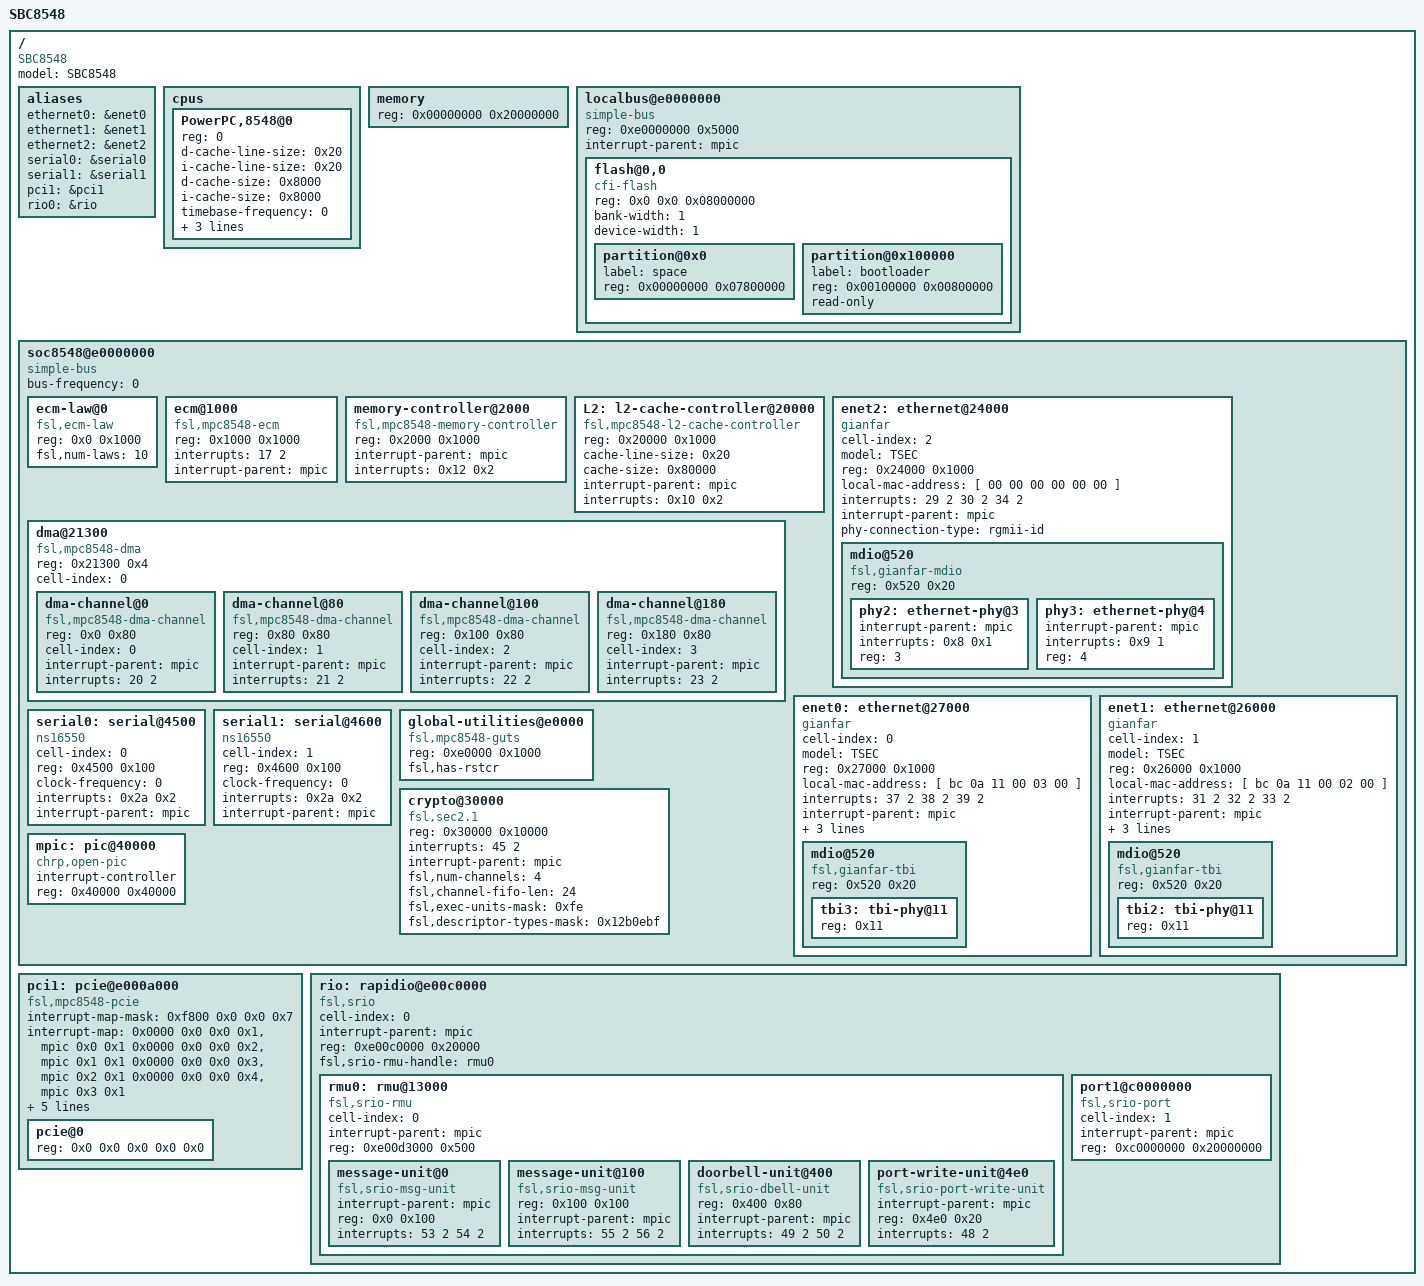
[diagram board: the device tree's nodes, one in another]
/*
 * SBC8548 Device Tree Source
 *
 * Copyright 2007 Wind River Systems Inc.
 *
 * Paul Gortmaker (see MAINTAINERS for contact information)
 *
 * This program is free software; you can redistribute  it and/or modify it
 * under  the terms of  the GNU General  Public License as published by the
 * Free Software Foundation;  either version 2 of the  License, or (at your
 * option) any later version.
 */


/dts-v1/;

/ {
	model = "SBC8548";
	compatible = "SBC8548";
	#address-cells = <1>;
	#size-cells = <1>;

	aliases {
		ethernet0 = &enet0;
                ethernet1 = &enet1;
                ethernet2 = &enet2;
		serial0 = &serial0;
		serial1 = &serial1;
		pci1 = &pci1;
		rio0 = &rio;
	};

	cpus {
		#address-cells = <1>;
		#size-cells = <0>;

		PowerPC,8548@0 {
			device_type = "cpu";
			reg = <0>;
			d-cache-line-size = <0x20>;	// 32 bytes
			i-cache-line-size = <0x20>;	// 32 bytes
			d-cache-size = <0x8000>;	// L1, 32K
			i-cache-size = <0x8000>;	// L1, 32K
			timebase-frequency = <0>;	// From uboot
			bus-frequency = <0>;
			clock-frequency = <0>;
			next-level-cache = <&L2>;
		};
	};

	memory {
		device_type = "memory";
		reg = <0x00000000 0x20000000>;
	};

	localbus@e0000000 {
		#address-cells = <2>;
		#size-cells = <1>;
		compatible = "simple-bus";
		reg = <0xe0000000 0x5000>;
		interrupt-parent = <&mpic>;

		ranges = <0x0 0x0 0xf8000000 0x08000000>;	/*64MB Flash*/


		flash@0,0 {
			#address-cells = <1>;
			#size-cells = <1>;
			compatible = "cfi-flash";
			reg = <0x0 0x0 0x08000000>;
			bank-width = <1>;
			device-width = <1>;
			partition@0x0 {
				label = "space";
				reg = <0x00000000 0x07800000>;
			};
			partition@0x100000 {
				label = "bootloader";
				reg = <0x00100000 0x00800000>;
				read-only;
			};
		};

		};

	soc8548@e0000000 {
		#address-cells = <1>;
		#size-cells = <1>;
		device_type = "soc";
		ranges = <0x00000000 0xe0000000 0x00100000>;
		bus-frequency = <0>;
		compatible = "simple-bus";

		ecm-law@0 {
			compatible = "fsl,ecm-law";
			reg = <0x0 0x1000>;
			fsl,num-laws = <10>;
		};

		ecm@1000 {
			compatible = "fsl,mpc8548-ecm", "fsl,ecm";
			reg = <0x1000 0x1000>;
			interrupts = <17 2>;
			interrupt-parent = <&mpic>;
		};

		memory-controller@2000 {
			compatible = "fsl,mpc8548-memory-controller";
			reg = <0x2000 0x1000>;
			interrupt-parent = <&mpic>;
			interrupts = <0x12 0x2>;
		};

		L2: l2-cache-controller@20000 {
			compatible = "fsl,mpc8548-l2-cache-controller";
			reg = <0x20000 0x1000>;
			cache-line-size = <0x20>;	// 32 bytes
			cache-size = <0x80000>;	// L2, 512K
			interrupt-parent = <&mpic>;
			interrupts = <0x10 0x2>;
		};

		dma@21300 {
			#address-cells = <1>;
			#size-cells = <1>;
			compatible = "fsl,mpc8548-dma", "fsl,eloplus-dma";
			reg = <0x21300 0x4>;
			ranges = <0x0 0x21100 0x200>;
			cell-index = <0>;
			dma-channel@0 {
				compatible = "fsl,mpc8548-dma-channel",
						"fsl,eloplus-dma-channel";
				reg = <0x0 0x80>;
				cell-index = <0>;
				interrupt-parent = <&mpic>;
				interrupts = <20 2>;
			};
			dma-channel@80 {
				compatible = "fsl,mpc8548-dma-channel",
						"fsl,eloplus-dma-channel";
				reg = <0x80 0x80>;
				cell-index = <1>;
				interrupt-parent = <&mpic>;
				interrupts = <21 2>;
			};
			dma-channel@100 {
				compatible = "fsl,mpc8548-dma-channel",
						"fsl,eloplus-dma-channel";
				reg = <0x100 0x80>;
				cell-index = <2>;
				interrupt-parent = <&mpic>;
				interrupts = <22 2>;
			};
			dma-channel@180 {
				compatible = "fsl,mpc8548-dma-channel",
						"fsl,eloplus-dma-channel";
				reg = <0x180 0x80>;
				cell-index = <3>;
				interrupt-parent = <&mpic>;
				interrupts = <23 2>;
			};
		};

		enet2: ethernet@24000 {
			#address-cells = <1>;
			#size-cells = <1>;
			cell-index = <2>;
			device_type = "network";
			model = "TSEC";
			compatible = "gianfar";
			reg = <0x24000 0x1000>;
			ranges = <0x0 0x24000 0x1000>;
			local-mac-address = [ 00 00 00 00 00 00 ];
			interrupts = <29 2 30  2 34 2>;
			interrupt-parent = <&mpic>;
                        phy-connection-type = "rgmii-id";
			mdio@520 {
				#address-cells = <1>;
				#size-cells = <0>;
				compatible = "fsl,gianfar-mdio";
				reg = <0x520 0x20>;
                                
                                phy2: ethernet-phy@3 {
                                        interrupt-parent = <&mpic>;
                                        interrupts = <0x8 0x1>;
                                        reg = <3>;
                                        device_type = "ethernet-phy";
                                };
                                phy3: ethernet-phy@4 {
                                        interrupt-parent = <&mpic>;
                                        interrupts = <0x9 1>;
                                        reg = <4>;
                                        device_type = "ethernet-phy";
                                };
			};
		};

		enet0: ethernet@27000 {
			#address-cells = <1>;
			#size-cells = <1>;
			cell-index = <0>;
			device_type = "network";
			model = "TSEC";
			compatible = "gianfar";
			reg = <0x27000 0x1000>;
			ranges = <0x0 0x27000 0x1000>;
			local-mac-address = [ bc 0a 11 00 03 00 ];
			interrupts = <37 2 38 2 39 2>;
			interrupt-parent = <&mpic>;
			phy-handle = <&phy3>;
                        tbi-handle = <&tbi3>;
                        phy-connection-type = "rgmii";
                        mdio@520 {
                                #address-cells = <1>;
                                #size-cells = <0>;
                                compatible = "fsl,gianfar-tbi";
                                reg = <0x520 0x20>;
                                tbi3:tbi-phy@11 {
					reg = <0x11>;
					device_type = "tbi-phy";
				};
                        };
		};
                enet1: ethernet@26000 {
                        #address-cells = <1>;
                        #size-cells = <1>;
                        cell-index = <1>;
                        device_type = "network";
                        model = "TSEC";
                        compatible = "gianfar";
                        reg = <0x26000 0x1000>;
                        ranges = <0x0 0x26000 0x1000>;
                        local-mac-address = [ bc 0a 11 00 02 00 ];
                        interrupts = <31 2 32 2 33 2>;
                        interrupt-parent = <&mpic>;
                        phy-handle = <&phy2>;
                        tbi-handle = <&tbi2>;
                        phy-connection-type = "rgmii-id";
                        mdio@520 {
                                #address-cells = <1>;
                                #size-cells = <0>;
                                compatible = "fsl,gianfar-tbi";
                                reg = <0x520 0x20>;
                                tbi2:tbi-phy@11 {
                                        reg = <0x11>;
                                        device_type = "tbi-phy";
                                };
                        };
                };

		serial0: serial@4500 {
			cell-index = <0>;
			device_type = "serial";
			compatible = "ns16550";
			reg = <0x4500 0x100>;	// reg base, size
			clock-frequency = <0>;	// should we fill in in uboot?
			interrupts = <0x2a 0x2>;
			interrupt-parent = <&mpic>;
		};

		serial1: serial@4600 {
			cell-index = <1>;
			device_type = "serial";
			compatible = "ns16550";
			reg = <0x4600 0x100>;	// reg base, size
			clock-frequency = <0>;	// should we fill in in uboot?
			interrupts = <0x2a 0x2>;
			interrupt-parent = <&mpic>;
		};

		global-utilities@e0000 {	//global utilities reg
			compatible = "fsl,mpc8548-guts";
			reg = <0xe0000 0x1000>;
			fsl,has-rstcr;
		};

		crypto@30000 {
			compatible = "fsl,sec2.1", "fsl,sec2.0";
			reg = <0x30000 0x10000>;
			interrupts = <45 2>;
			interrupt-parent = <&mpic>;
			fsl,num-channels = <4>;
			fsl,channel-fifo-len = <24>;
			fsl,exec-units-mask = <0xfe>;
			fsl,descriptor-types-mask = <0x12b0ebf>;
		};

		mpic: pic@40000 {
			interrupt-controller;
			#address-cells = <0>;
			#interrupt-cells = <2>;
			reg = <0x40000 0x40000>;
			compatible = "chrp,open-pic";
			device_type = "open-pic";
		};
	};
	pci1: pcie@e000a000 {
		interrupt-map-mask = <0xf800 0x0 0x0 0x7>;
		interrupt-map = <

			/* IDSEL 0x0 (PEX) */
			0x0000 0x0 0x0 0x1 &mpic 0x0 0x1
			0x0000 0x0 0x0 0x2 &mpic 0x1 0x1
			0x0000 0x0 0x0 0x3 &mpic 0x2 0x1
			0x0000 0x0 0x0 0x4 &mpic 0x3 0x1>;

		interrupt-parent = <&mpic>;
		interrupts = <0x1a 0x2>;
		bus-range = <0x0 0xff>;
		ranges = <0x02000000 0x0 0xa0000000 0xa0000000 0x0 0x20000000
			  0x01000000 0x0 0x00000000 0xe2800000 0x0 0x08000000>;
		clock-frequency = <33000000>;
		#interrupt-cells = <1>;
		#size-cells = <2>;
		#address-cells = <3>;
		reg = <0xe000a000 0x1000>;
		compatible = "fsl,mpc8548-pcie";
		device_type = "pci";
		pcie@0 {
			reg = <0x0 0x0 0x0 0x0 0x0>;
			#size-cells = <2>;
			#address-cells = <3>;
			device_type = "pci";
			ranges = <0x02000000 0x0 0xa0000000
				  0x02000000 0x0 0xa0000000
				  0x0 0x20000000

				       0x01000000 0x0 0x00000000
				       0x01000000 0x0 0x00000000
				       0x0 0x00800000>;
		};
	};
	rio: rapidio@e00c0000 {
	  cell-index = <0>;
	  #address-cells = <1>;
	  #size-cells = <1>;
		compatible = "fsl,srio";
		interrupt-parent = <&mpic>;
		reg = <0xe00c0000 0x20000>; 
	  fsl,srio-rmu-handle = <&rmu0>;
	  
			rmu0: rmu@13000 { 
			cell-index = <0>;
		  #address-cells = <1>;
		  #size-cells = <1>;
			compatible = "fsl,srio-rmu";
			interrupt-parent = <&mpic>;
			reg = <0xe00d3000 0x500>;
			ranges = <0x0 0xe00d3000 0x500>;
			
			message-unit@0 {
				compatible = "fsl,srio-msg-unit";
				#interrupt-cells = <2>;
				interrupt-parent = <&mpic>;
				reg = <0x0 0x100>; 
				interrupts = < 53 2 54 2 >;
			};
			message-unit@100 {
				compatible = "fsl,srio-msg-unit";
				reg = <0x100 0x100>;
				#interrupt-cells = <2>;
				interrupt-parent = <&mpic>;
				interrupts = <
					55 2   /* msg2_tx_irq */
					56 2 >;/* msg2_rx_irq */
			};
			doorbell-unit@400 {
				compatible = "fsl,srio-dbell-unit";
				reg = <0x400 0x80>;
				#interrupt-cells = <2>;
				interrupt-parent = <&mpic>;
				interrupts = <
					49 2   /* bell_outb_irq */
					50 2 >;/* bell_inb_irq */
			};
			port-write-unit@4e0 {
				compatible = "fsl,srio-port-write-unit";
				#interrupt-cells = <2>;
				interrupt-parent = <&mpic>;
				reg = <0x4e0 0x20>;
				interrupts = <48 2 >;
			};
		}; 
		port1@c0000000 {
		  compatible = "fsl,srio-port";
			#address-cells = <1>;
			#size-cells = <1>;
			cell-index = <1>;
			interrupt-parent = <&mpic>;
			reg = <0xc0000000 0x20000000>;
			ranges = <0x0 0xc0000000 0x20000000>;    
		};
	};
};
